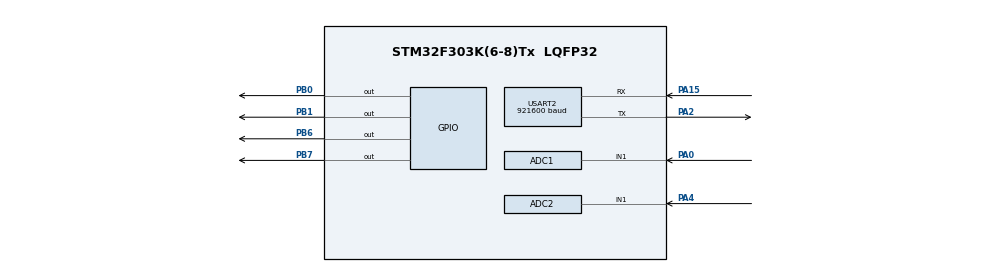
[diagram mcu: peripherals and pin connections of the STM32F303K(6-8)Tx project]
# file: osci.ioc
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ADC1.Channel-0\#ChannelRegularConversion=ADC_CHANNEL_1
ADC1.ClockPrescaler=ADC_CLOCK_SYNC_PCLK_DIV1
ADC1.DMAContinuousRequests=DISABLE
ADC1.EnableAnalogWatchDog1=false
ADC1.ExternalTrigConv=ADC_EXTERNALTRIGCONV_T1_TRGO
ADC1.NbrOfConversionFlag=1
ADC1.Offset-0\#ChannelRegularConversion=0
ADC1.OffsetNumber-0\#ChannelRegularConversion=ADC_OFFSET_NONE
ADC1.Rank-0\#ChannelRegularConversion=1
ADC1.SamplingTime-0\#ChannelRegularConversion=ADC_SAMPLETIME_19CYCLES_5
ADC1.SubFamily=STM32F303x8
ADC1.master=1
ADC2.Channel-0\#ChannelRegularConversion=ADC_CHANNEL_1
ADC2.ClockPrescaler=ADC_CLOCK_SYNC_PCLK_DIV1
ADC2.EnableAnalogWatchDog2=false
ADC2.ExternalTrigConv=ADC_EXTERNALTRIGCONV_T2_TRGO
ADC2.NbrOfConversionFlag=1
ADC2.Offset-0\#ChannelRegularConversion=0
ADC2.OffsetNumber-0\#ChannelRegularConversion=ADC_OFFSET_NONE
ADC2.Rank-0\#ChannelRegularConversion=1
ADC2.SamplingTime-0\#ChannelRegularConversion=ADC_SAMPLETIME_19CYCLES_5
ADC2.SubFamily=STM32F303x8
Dma.ADC1.0.Direction=DMA_PERIPH_TO_MEMORY
Dma.ADC1.0.Instance=DMA1_Channel1
Dma.ADC1.0.MemDataAlignment=DMA_MDATAALIGN_HALFWORD
Dma.ADC1.0.MemInc=DMA_MINC_ENABLE
Dma.ADC1.0.Mode=DMA_NORMAL
Dma.ADC1.0.PeriphDataAlignment=DMA_PDATAALIGN_HALFWORD
Dma.ADC1.0.PeriphInc=DMA_PINC_DISABLE
Dma.ADC1.0.Priority=DMA_PRIORITY_VERY_HIGH
Dma.ADC2.1.Direction=DMA_PERIPH_TO_MEMORY
Dma.ADC2.1.Instance=DMA1_Channel2
Dma.ADC2.1.MemDataAlignment=DMA_MDATAALIGN_HALFWORD
Dma.ADC2.1.MemInc=DMA_MINC_ENABLE
Dma.ADC2.1.Mode=DMA_NORMAL
Dma.ADC2.1.PeriphDataAlignment=DMA_PDATAALIGN_HALFWORD
Dma.ADC2.1.PeriphInc=DMA_PINC_DISABLE
Dma.ADC2.1.Priority=DMA_PRIORITY_VERY_HIGH
Dma.Request0=ADC1
Dma.Request1=ADC2
Dma.Request2=USART2_RX
Dma.Request3=USART2_TX
Dma.USART2_RX.2.Direction=DMA_PERIPH_TO_MEMORY
Dma.USART2_RX.2.Instance=DMA1_Channel6
Dma.USART2_RX.2.MemDataAlignment=DMA_MDATAALIGN_BYTE
Dma.USART2_RX.2.MemInc=DMA_MINC_ENABLE
Dma.USART2_RX.2.Mode=DMA_CIRCULAR
Dma.USART2_RX.2.PeriphDataAlignment=DMA_PDATAALIGN_BYTE
Dma.USART2_RX.2.PeriphInc=DMA_PINC_DISABLE
Dma.USART2_RX.2.Priority=DMA_PRIORITY_LOW
Dma.USART2_TX.3.Direction=DMA_MEMORY_TO_PERIPH
Dma.USART2_TX.3.Instance=DMA1_Channel7
Dma.USART2_TX.3.MemDataAlignment=DMA_MDATAALIGN_BYTE
Dma.USART2_TX.3.MemInc=DMA_MINC_ENABLE
Dma.USART2_TX.3.Mode=DMA_NORMAL
Dma.USART2_TX.3.PeriphDataAlignment=DMA_PDATAALIGN_BYTE
Dma.USART2_TX.3.PeriphInc=DMA_PINC_DISABLE
Dma.USART2_TX.3.Priority=DMA_PRIORITY_LOW
Mcu.Family=STM32F3
Mcu.Name=STM32F303K(6-8)Tx
Mcu.Package=LQFP32
NVIC.ADC1_2_IRQn=true\:0\:0\:false\:false\:true\:true\:true
NVIC.DMA1_Channel1_IRQn=true\:0\:0\:false\:false\:true\:false\:true
NVIC.DMA1_Channel2_IRQn=true\:0\:0\:false\:false\:true\:false\:true
NVIC.DMA1_Channel6_IRQn=true\:0\:0\:false\:false\:true\:false\:true
NVIC.DMA1_Channel7_IRQn=true\:0\:0\:false\:false\:true\:false\:true
NVIC.PriorityGroup=NVIC_PRIORITYGROUP_4
NVIC.TIM1_BRK_TIM15_IRQn=true\:0\:0\:false\:false\:true\:true\:true
NVIC.TIM3_IRQn=true\:0\:0\:false\:false\:true\:true\:true
PA0.Mode=IN1-Single-Ended
PA0.Signal=ADC1_IN1
PA15.Mode=Asynchronous
PA15.Signal=USART2_RX
PA2.Mode=Asynchronous
PA2.Signal=USART2_TX
PA4.Mode=IN1-Single-Ended
PA4.Signal=ADC2_IN1
PB0.Signal=GPIO_Output
PB1.Signal=GPIO_Output
PB6.Signal=GPIO_Output
PB7.Signal=GPIO_Output
ProjectManager.HeapSize=0x200
ProjectManager.StackSize=0x400
ProjectManager.TargetToolchain=STM32CubeIDE
RCC.AHBFreq_Value=32000000
RCC.APB1Freq_Value=32000000
RCC.APB1TimFreq_Value=32000000
RCC.APB2Freq_Value=32000000
RCC.APB2TimFreq_Value=32000000
RCC.CortexFreq_Value=32000000
RCC.HCLKFreq_Value=32000000
RCC.HSE_VALUE=8000000
RCC.HSI_VALUE=8000000
RCC.PLLMUL=RCC_PLL_MUL8
RCC.SYSCLKFreq_VALUE=32000000
RCC.SYSCLKSourceVirtual=RCC_SYSCLKSOURCE_PLLCLK
TIM1.Period=1
TIM1.Prescaler=0
TIM1.TIM_MasterOutputTrigger=TIM_TRGO_UPDATE
TIM1.TIM_MasterOutputTrigger2=TIM_TRGO2_RESET
TIM1.TIM_MasterSlaveMode=TIM_MASTERSLAVEMODE_DISABLE
TIM15.Period=999
TIM15.Prescaler=31999
TIM2.Period=1
TIM2.Prescaler=0
TIM2.TIM_MasterOutputTrigger=TIM_TRGO_UPDATE
TIM3.Period=999
TIM3.Prescaler=31999
USART2.BaudRate=921600
USART2.VirtualMode-Asynchronous=VM_ASYNC
VP_TIM15_VS_ClockSourceINT.Mode=Internal
VP_TIM1_VS_ClockSourceINT.Mode=Internal
VP_TIM2_VS_ClockSourceINT.Mode=Internal
VP_TIM3_VS_ClockSourceINT.Mode=Internal
board=custom

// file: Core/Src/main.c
/* USER CODE BEGIN Header */
/**
  ******************************************************************************
  * @file           : main.c
  * @brief          : Main program body
  ******************************************************************************
  * @attention
  *
  * <h2><center>&copy; Copyright (c) 2019 STMicroelectronics.
  * All rights reserved.</center></h2>
  *
  * This software component is licensed by ST under BSD 3-Clause license,
  * the "License"; You may not use this file except in compliance with the
  * License. You may obtain a copy of the License at:
  *                        opensource.org/licenses/BSD-3-Clause
  *
  ******************************************************************************
  */
/* USER CODE END Header */

#include "main.h"
#include "adc.h"
#include "dma.h"
#include "tim.h"
#include "usart.h"
#include "gpio.h"

/* USER CODE BEGIN Includes */
#include "osci_defines.h"
#include "osci_data_structures.h"
#include "osci.h"
/* USER CODE END Includes */

void SystemClock_Config(void);

int main(void)
{

  /* MCU Configuration--------------------------------------------------------*/

  /* Reset of all peripherals, Initializes the Flash interface and the Systick. */

  LL_APB2_GRP1_EnableClock(LL_APB2_GRP1_PERIPH_SYSCFG);
  LL_APB1_GRP1_EnableClock(LL_APB1_GRP1_PERIPH_PWR);

  NVIC_SetPriorityGrouping(NVIC_PRIORITYGROUP_4);

  /* System interrupt init*/

  /* Configure the system clock */
  SystemClock_Config();

  /* Initialize all configured peripherals */
  MX_GPIO_Init();
  MX_DMA_Init();
  MX_ADC1_Init();
  MX_ADC2_Init();
  MX_TIM1_Init();
  MX_TIM2_Init();
  MX_USART2_UART_Init();
  MX_TIM3_Init();
  MX_TIM15_Init();
  /* USER CODE BEGIN 2 */

  LL_GPIO_SetOutputPin(GPIOB, LL_GPIO_PIN_7);
  LL_GPIO_SetOutputPin(GPIOB, LL_GPIO_PIN_6);

  Osci_Application* app = OSCI_init();
  app_IT_reference = app;

  /* USER CODE END 2 */

  /* Infinite loop */
  /* USER CODE BEGIN WHILE */
  while (1)
  {
	  OSCI_transceiver_update(&app->transceiver);
	  OSCI_channel_update(&app->xChannelStateMachine);
	  OSCI_channel_update(&app->yChannelStateMachine);
    /* USER CODE END WHILE */

  }
}

void SystemClock_Config(void)
{
  LL_FLASH_SetLatency(LL_FLASH_LATENCY_1);

  if(LL_FLASH_GetLatency() != LL_FLASH_LATENCY_1)
  {
  Error_Handler();
  }
  LL_RCC_HSI_Enable();

   /* Wait till HSI is ready */
  while(LL_RCC_HSI_IsReady() != 1)
  {

  }
  LL_RCC_HSI_SetCalibTrimming(16);
  LL_RCC_PLL_ConfigDomain_SYS(LL_RCC_PLLSOURCE_HSI_DIV_2, LL_RCC_PLL_MUL_8);
  LL_RCC_PLL_Enable();

   /* Wait till PLL is ready */
  while(LL_RCC_PLL_IsReady() != 1)
  {

  }
  LL_RCC_SetAHBPrescaler(LL_RCC_SYSCLK_DIV_1);
  LL_RCC_SetAPB1Prescaler(LL_RCC_APB1_DIV_1);
  LL_RCC_SetAPB2Prescaler(LL_RCC_APB1_DIV_1);
  LL_RCC_SetSysClkSource(LL_RCC_SYS_CLKSOURCE_PLL);

   /* Wait till System clock is ready */
  while(LL_RCC_GetSysClkSource() != LL_RCC_SYS_CLKSOURCE_STATUS_PLL)
  {

  }
  LL_Init1msTick(32000000);
  LL_SYSTICK_SetClkSource(LL_SYSTICK_CLKSOURCE_HCLK);
  LL_SetSystemCoreClock(32000000);
  LL_RCC_SetTIMClockSource(LL_RCC_TIM1_CLKSOURCE_PCLK2);
}

void Error_Handler(void)
{
}

/************************ (C) COPYRIGHT STMicroelectronics *****END OF FILE****/
